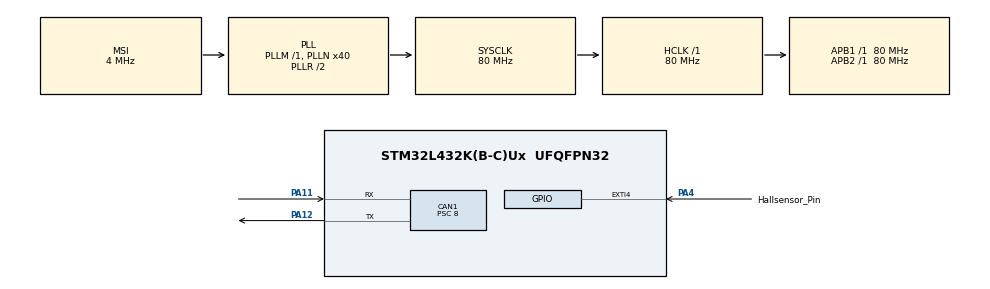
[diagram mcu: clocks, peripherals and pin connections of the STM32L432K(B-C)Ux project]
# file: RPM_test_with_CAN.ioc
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CAN1.BS1=CAN_BS1_6TQ
CAN1.BS2=CAN_BS2_3TQ
CAN1.CalculateBaudRate=1000000
CAN1.CalculateTimeBit=1000
CAN1.CalculateTimeQuantum=100.0
CAN1.Prescaler=8
Mcu.Family=STM32L4
Mcu.Name=STM32L432K(B-C)Ux
Mcu.Package=UFQFPN32
NVIC.CAN1_TX_IRQn=true\:0\:0\:true\:false\:true\:true\:true\:true
NVIC.EXTI4_IRQn=true\:0\:0\:true\:false\:true\:true\:true\:true
NVIC.FPU_IRQn=true\:0\:0\:false\:false\:true\:true\:false\:true
NVIC.PriorityGroup=NVIC_PRIORITYGROUP_4
NVIC.TIM2_IRQn=true\:0\:0\:false\:false\:true\:true\:true\:true
PA11.Mode=CAN_Activate
PA11.Signal=CAN1_RX
PA12.Mode=CAN_Activate
PA12.Signal=CAN1_TX
PA13\ (JTMS-SWDIO).Mode=Serial_Wire
PA13\ (JTMS-SWDIO).Signal=SYS_JTMS-SWDIO
PA14\ (JTCK-SWCLK).Mode=Serial_Wire
PA14\ (JTCK-SWCLK).Signal=SYS_JTCK-SWCLK
PA4.GPIO_Label=Hallsensor_Pin
PA4.GPIO_ModeDefaultEXTI=GPIO_MODE_IT_RISING
PA4.GPIO_PuPd=GPIO_PULLUP
PA4.Signal=GPXTI4
ProjectManager.HeapSize=0x200
ProjectManager.StackSize=0x400
ProjectManager.TargetToolchain=STM32CubeIDE
RCC.AHBFreq_Value=80000000
RCC.APB1Freq_Value=80000000
RCC.APB1TimFreq_Value=80000000
RCC.APB2Freq_Value=80000000
RCC.APB2TimFreq_Value=80000000
RCC.CortexFreq_Value=80000000
RCC.HCLKFreq_Value=80000000
RCC.HSE_VALUE=8000000
RCC.HSI48_VALUE=48000000
RCC.HSI_VALUE=16000000
RCC.LSE_VALUE=32768
RCC.MSI_VALUE=4000000
RCC.PLLN=40
RCC.SYSCLKFreq_VALUE=80000000
RCC.SYSCLKSource=RCC_SYSCLKSOURCE_PLLCLK
RCC.VCOOutputFreq_Value=160000000
TIM2.Prescaler=79
VP_TIM2_VS_ClockSourceINT.Mode=Internal
board=custom

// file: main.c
/* USER CODE BEGIN Header */
/**
  ******************************************************************************
  * @file           : main.c
  * @brief          : Main program body
  ******************************************************************************
  * @attention
  *
  * Copyright (c) 2022 STMicroelectronics.
  * All rights reserved.
  *
  * This software is licensed under terms that can be found in the LICENSE file
  * in the root directory of this software component.
  * If no LICENSE file comes with this software, it is provided AS-IS.
  *
  ******************************************************************************
  */
/* USER CODE END Header */
#include "main.h"

CAN_HandleTypeDef hcan1;

TIM_HandleTypeDef htim2;

void SystemClock_Config(void);
static void MX_GPIO_Init(void);
static void MX_CAN1_Init(void);
static void MX_TIM2_Init(void);

/* USER CODE BEGIN 0 */
uint32_t curr_time_stamp = 0;
uint32_t curr_time = 0;
uint32_t prev_time_stamp = 0;
uint32_t prev_time = 0;
uint32_t duration = 0;
uint32_t loop_time = 0;
uint32_t rpm = 0;
uint32_t prev_rpm = 0;
uint32_t constant_ = 60*500000;
CAN_FilterTypeDef canFilter1;
CAN_TxHeaderTypeDef canTxHeader;
uint8_t canTx0Data[4];
uint32_t txMailBox;
/* USER CODE END 0 */

int main(void)
{

  /* MCU Configuration--------------------------------------------------------*/

  /* Reset of all peripherals, Initializes the Flash interface and the Systick. */
  HAL_Init();

  /* Configure the system clock */
  SystemClock_Config();

  /* Initialize all configured peripherals */
  MX_GPIO_Init();
  MX_CAN1_Init();
  MX_TIM2_Init();
  /* USER CODE BEGIN 2 */
  HAL_CAN_Start(&hcan1);
  HAL_TIM_Base_Start(&htim2);
  __HAL_TIM_SET_COUNTER(&htim2, 0);
  curr_time_stamp = __HAL_TIM_GET_COUNTER(&htim2);
  prev_time_stamp = curr_time_stamp;
  /* USER CODE END 2 */

  /* Infinite loop */
  while (1)
  {

    /* USER CODE BEGIN 3 */
	  curr_time_stamp = __HAL_TIM_GET_COUNTER(&htim2);
	  loop_time = curr_time_stamp - prev_time_stamp;
	  if(loop_time > 10000){
		  canTxHeader.StdId = 0x101;
		  canTxHeader.RTR = CAN_RTR_DATA;
		  canTxHeader.IDE = CAN_ID_STD;
		  canTxHeader.DLC = 4;

		  if ((curr_time_stamp - prev_time) > 500000)
				  rpm = 0;

		  data_to_Hex(rpm);

		  txMailBox = HAL_CAN_GetTxMailboxesFreeLevel(&hcan1);
		  HAL_CAN_AddTxMessage(&hcan1, &canTxHeader, canTx0Data, &txMailBox);
		  prev_time_stamp = curr_time_stamp;
	  }

  }
  /* USER CODE END 3 */
}

void SystemClock_Config(void)
{
  RCC_OscInitTypeDef RCC_OscInitStruct = {0};
  RCC_ClkInitTypeDef RCC_ClkInitStruct = {0};

  /** Configure the main internal regulator output voltage
  */
  if (HAL_PWREx_ControlVoltageScaling(PWR_REGULATOR_VOLTAGE_SCALE1) != HAL_OK)
  {
    Error_Handler();
  }

  /** Initializes the RCC Oscillators according to the specified parameters
  * in the RCC_OscInitTypeDef structure.
  */
  RCC_OscInitStruct.OscillatorType = RCC_OSCILLATORTYPE_MSI;
  RCC_OscInitStruct.MSIState = RCC_MSI_ON;
  RCC_OscInitStruct.MSICalibrationValue = 0;
  RCC_OscInitStruct.MSIClockRange = RCC_MSIRANGE_6;
  RCC_OscInitStruct.PLL.PLLState = RCC_PLL_ON;
  RCC_OscInitStruct.PLL.PLLSource = RCC_PLLSOURCE_MSI;
  RCC_OscInitStruct.PLL.PLLM = 1;
  RCC_OscInitStruct.PLL.PLLN = 40;
  RCC_OscInitStruct.PLL.PLLP = RCC_PLLP_DIV7;
  RCC_OscInitStruct.PLL.PLLQ = RCC_PLLQ_DIV2;
  RCC_OscInitStruct.PLL.PLLR = RCC_PLLR_DIV2;
  if (HAL_RCC_OscConfig(&RCC_OscInitStruct) != HAL_OK)
  {
    Error_Handler();
  }

  /** Initializes the CPU, AHB and APB buses clocks
  */
  RCC_ClkInitStruct.ClockType = RCC_CLOCKTYPE_HCLK|RCC_CLOCKTYPE_SYSCLK
                              |RCC_CLOCKTYPE_PCLK1|RCC_CLOCKTYPE_PCLK2;
  RCC_ClkInitStruct.SYSCLKSource = RCC_SYSCLKSOURCE_PLLCLK;
  RCC_ClkInitStruct.AHBCLKDivider = RCC_SYSCLK_DIV1;
  RCC_ClkInitStruct.APB1CLKDivider = RCC_HCLK_DIV1;
  RCC_ClkInitStruct.APB2CLKDivider = RCC_HCLK_DIV1;

  if (HAL_RCC_ClockConfig(&RCC_ClkInitStruct, FLASH_LATENCY_4) != HAL_OK)
  {
    Error_Handler();
  }
}

static void MX_CAN1_Init(void)
{

  hcan1.Instance = CAN1;
  hcan1.Init.Prescaler = 8;
  hcan1.Init.Mode = CAN_MODE_NORMAL;
  hcan1.Init.SyncJumpWidth = CAN_SJW_1TQ;
  hcan1.Init.TimeSeg1 = CAN_BS1_6TQ;
  hcan1.Init.TimeSeg2 = CAN_BS2_3TQ;
  hcan1.Init.TimeTriggeredMode = DISABLE;
  hcan1.Init.AutoBusOff = DISABLE;
  hcan1.Init.AutoWakeUp = DISABLE;
  hcan1.Init.AutoRetransmission = DISABLE;
  hcan1.Init.ReceiveFifoLocked = DISABLE;
  hcan1.Init.TransmitFifoPriority = DISABLE;
  if (HAL_CAN_Init(&hcan1) != HAL_OK)
  {
    Error_Handler();
  }

}

static void MX_TIM2_Init(void)
{

  TIM_ClockConfigTypeDef sClockSourceConfig = {0};
  TIM_MasterConfigTypeDef sMasterConfig = {0};

  htim2.Instance = TIM2;
  htim2.Init.Prescaler = 79;
  htim2.Init.CounterMode = TIM_COUNTERMODE_UP;
  htim2.Init.Period = 4294967295;
  htim2.Init.ClockDivision = TIM_CLOCKDIVISION_DIV1;
  htim2.Init.AutoReloadPreload = TIM_AUTORELOAD_PRELOAD_DISABLE;
  if (HAL_TIM_Base_Init(&htim2) != HAL_OK)
  {
    Error_Handler();
  }
  sClockSourceConfig.ClockSource = TIM_CLOCKSOURCE_INTERNAL;
  if (HAL_TIM_ConfigClockSource(&htim2, &sClockSourceConfig) != HAL_OK)
  {
    Error_Handler();
  }
  sMasterConfig.MasterOutputTrigger = TIM_TRGO_RESET;
  sMasterConfig.MasterSlaveMode = TIM_MASTERSLAVEMODE_DISABLE;
  if (HAL_TIMEx_MasterConfigSynchronization(&htim2, &sMasterConfig) != HAL_OK)
  {
    Error_Handler();
  }

}

static void MX_GPIO_Init(void)
{
  GPIO_InitTypeDef GPIO_InitStruct = {0};

  /* GPIO Ports Clock Enable */
  __HAL_RCC_GPIOA_CLK_ENABLE();

  /*Configure GPIO pin : Hallsensor_Pin_Pin */
  GPIO_InitStruct.Pin = Hallsensor_Pin_Pin;
  GPIO_InitStruct.Mode = GPIO_MODE_IT_RISING;
  GPIO_InitStruct.Pull = GPIO_PULLUP;
  HAL_GPIO_Init(Hallsensor_Pin_GPIO_Port, &GPIO_InitStruct);

  /* EXTI interrupt init*/
  HAL_NVIC_SetPriority(EXTI4_IRQn, 0, 0);
  HAL_NVIC_EnableIRQ(EXTI4_IRQn);

}

/* USER CODE BEGIN 4 */
void data_to_Hex(uint32_t data)
{
	for(int i = 0; i < 4;i++)
	{
		canTx0Data[3-i] = data >> 8*i;
		//canTx0Data[3-i] = 0x01;
	}
}

void HAL_GPIO_EXTI_Callback(uint16_t GPIO_Pin)
{
	curr_time =__HAL_TIM_GET_COUNTER(&htim2);
	duration = (uint32_t) curr_time - prev_time;
	rpm = (uint32_t) 1000000*60/duration;
	prev_time = curr_time;
}
/* USER CODE END 4 */

void Error_Handler(void)
{
  __disable_irq();
  while (1)
  {
  }
}
